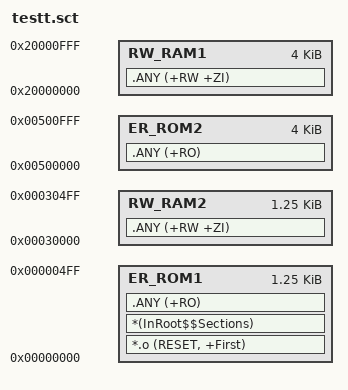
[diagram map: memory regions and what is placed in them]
; *************************************************************
; *** Scatter-Loading Description File generated by uVision ***
; *************************************************************

LR_ROM1 0x00000000 0x00000500  {    ; load region size_region
  ER_ROM1 0x00000000 0x00000500  {  ; load address = execution address
   *.o (RESET, +First)
   *(InRoot$$Sections)
   .ANY (+RO)
  }
  RW_RAM1 0x20000000 0x00001000  {  ; RW data
   .ANY (+RW +ZI)
  }
  RW_RAM2 0x00030000 0x00000500  {
   .ANY (+RW +ZI)
  }
}

LR_ROM2 0x00500000 0x00001000  {
  ER_ROM2 0x00500000 0x00001000  {  ; load address = execution address
   .ANY (+RO)
  }
}
